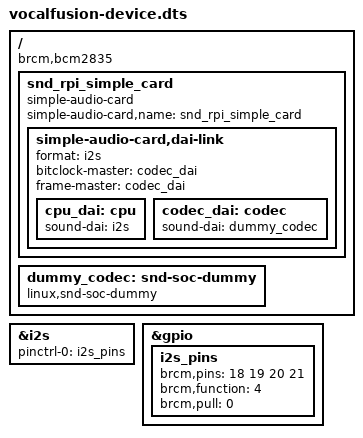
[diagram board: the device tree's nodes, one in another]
/dts-v1/;
/plugin/;

/ {
	compatible = "brcm,bcm2835";

    fragment@0 {
        target-path = "/";
        __overlay__ {
            snd_rpi_simple_card: snd_rpi_simple_card {
                compatible = "simple-audio-card";
                simple-audio-card,name = "snd_rpi_simple_card";
                status = "okay";

                simple-audio-card,dai-link {
                    // https://github.com/raspberrypi/linux/blob/rpi-6.1.y/Documentation/devicetree/bindings/sound/simple-card.yaml
                    format = "i2s";
                    bitclock-master = <&codec_dai>;
                    frame-master = <&codec_dai>;

                    cpu_dai: cpu {
                        sound-dai = <&i2s>;
                    };

                    codec_dai: codec {
                        sound-dai = <&dummy_codec>;
                    };
                };
            };

            dummy_codec: snd-soc-dummy {
                compatible = "linux,snd-soc-dummy";
                #sound-dai-cells = <0>;
                status = "okay";
            };
        };
    };

    fragment@1 {
        target = <&i2s>;
        __overlay__ {
            // https://www.kernel.org/doc/Documentation/devicetree/bindings/pinctrl/pinctrl-bindings.txt
            status = "okay";
            #sound-dai-cells = <0>;
            pinctrl-names = "default";
            pinctrl-0 = <&i2s_pins>;
        };
    };

    fragment@2 {
        target = <&gpio>;
        __overlay__ {
            // https://www.kernel.org/doc/Documentation/devicetree/bindings/pinctrl/brcm%2Cbcm2835-gpio.txt
            i2s_pins: i2s_pins {
                brcm,pins = <18 19 20 21>;
                brcm,function = <4>; // alt-0
                brcm,pull = <0>;
            };
        };
    };

    __overrides__ {
        master = <&codec_dai>,"bitclock-master?",
                 <&codec_dai>,"frame-master?";
        card_name = <&snd_rpi_simple_card>,"simple-audio-card,name";
    };
};
